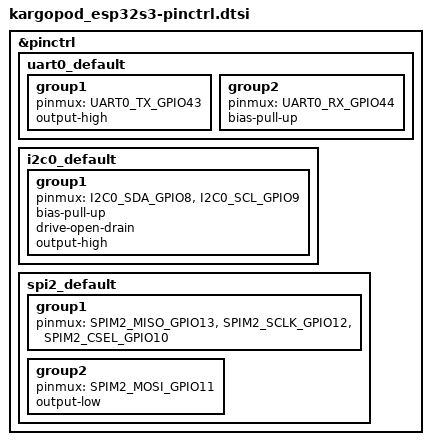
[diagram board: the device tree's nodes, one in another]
/*
 * Copyright (c) 2025 Kargo Chain
 * SPDX-License-Identifier: Apache-2.0
 */

#include <zephyr/dt-bindings/pinctrl/esp-pinctrl-common.h>
#include <dt-bindings/pinctrl/esp32s3-pinctrl.h>
#include <zephyr/dt-bindings/pinctrl/esp32s3-gpio-sigmap.h>

&pinctrl {
	uart0_default: uart0_default {
		group1 {
			pinmux = <UART0_TX_GPIO43>;
			output-high;
		};
		group2 {
			pinmux = <UART0_RX_GPIO44>;
			bias-pull-up;
		};
	};

	i2c0_default: i2c0_default {
		group1 {
			pinmux = <I2C0_SDA_GPIO8>,
				 <I2C0_SCL_GPIO9>;
			bias-pull-up;
			drive-open-drain;
			output-high;
		};
	};

	spi2_default: spi2_default {
		group1 {
			pinmux = <SPIM2_MISO_GPIO13>,
				 <SPIM2_SCLK_GPIO12>,
				 <SPIM2_CSEL_GPIO10>;
		};
		group2 {
			pinmux = <SPIM2_MOSI_GPIO11>;
			output-low;
		};
	};
};
